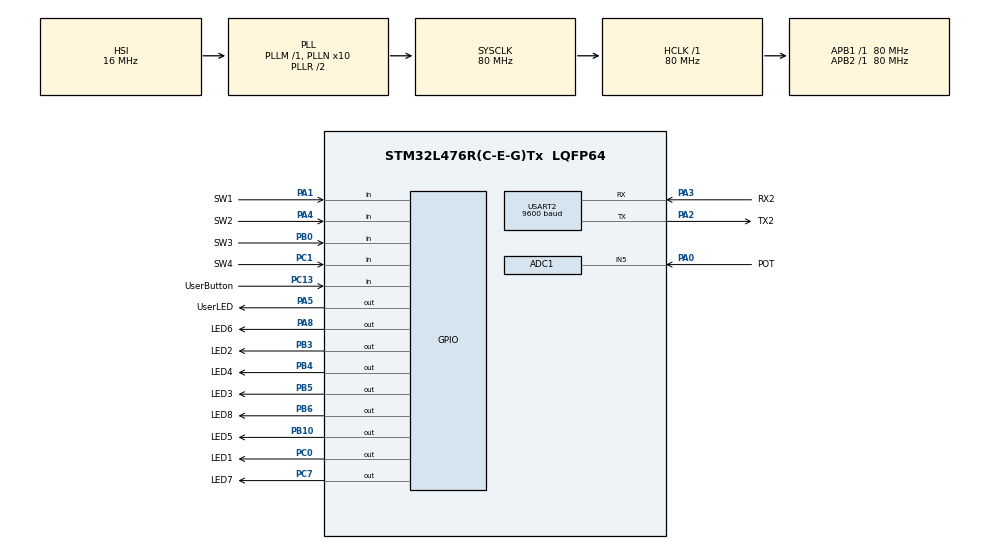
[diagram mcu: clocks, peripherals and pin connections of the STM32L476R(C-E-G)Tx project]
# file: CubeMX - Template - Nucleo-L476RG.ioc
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ADC1.Channel-0\#ChannelRegularConversion=ADC_CHANNEL_5
ADC1.NbrOfConversionFlag=1
ADC1.OffsetNumber-0\#ChannelRegularConversion=ADC_OFFSET_NONE
ADC1.Overrun=ADC_OVR_DATA_OVERWRITTEN
ADC1.Rank-0\#ChannelRegularConversion=1
ADC1.Resolution=ADC_RESOLUTION_12B
ADC1.SamplingTime-0\#ChannelRegularConversion=ADC_SAMPLETIME_2CYCLES_5
ADC1.master=1
Mcu.Family=STM32L4
Mcu.Name=STM32L476R(C-E-G)Tx
Mcu.Package=LQFP64
NVIC.PriorityGroup=NVIC_PRIORITYGROUP_4
NVIC.TIM6_DAC_IRQn=true\:0\:0\:false\:false\:true\:true\:true\:true
NVIC.USART2_IRQn=true\:0\:0\:false\:false\:true\:true\:true\:true
PA0.GPIO_Label=POT
PA0.Signal=ADCx_IN5
PA1.GPIO_Label=SW1
PA1.Signal=GPIO_Input
PA13\ (JTMS-SWDIO).GPIO_Label=TMS
PA13\ (JTMS-SWDIO).Mode=Serial_Wire
PA13\ (JTMS-SWDIO).Signal=SYS_JTMS-SWDIO
PA14\ (JTCK-SWCLK).GPIO_Label=TCK
PA14\ (JTCK-SWCLK).Mode=Serial_Wire
PA14\ (JTCK-SWCLK).Signal=SYS_JTCK-SWCLK
PA2.GPIO_Label=TX2
PA2.GPIO_Mode=GPIO_MODE_AF_PP
PA2.GPIO_PuPd=GPIO_NOPULL
PA2.GPIO_Speed=GPIO_SPEED_FREQ_VERY_HIGH
PA2.Mode=Asynchronous
PA2.Signal=USART2_TX
PA3.GPIO_Label=RX2
PA3.GPIO_Mode=GPIO_MODE_AF_PP
PA3.GPIO_PuPd=GPIO_NOPULL
PA3.GPIO_Speed=GPIO_SPEED_FREQ_VERY_HIGH
PA3.Mode=Asynchronous
PA3.Signal=USART2_RX
PA4.GPIO_Label=SW2
PA4.Signal=GPIO_Input
PA5.GPIO_Label=UserLED
PA5.GPIO_ModeDefaultOutputPP=GPIO_MODE_OUTPUT_PP
PA5.GPIO_PuPd=GPIO_NOPULL
PA5.GPIO_Speed=GPIO_SPEED_FREQ_LOW
PA5.Signal=GPIO_Output
PA8.GPIO_Label=LED6
PA8.Signal=GPIO_Output
PB0.GPIO_Label=SW3
PB0.Signal=GPIO_Input
PB10.GPIO_Label=LED5
PB10.Signal=GPIO_Output
PB3\ (JTDO-TRACESWO).GPIO_Label=LED2
PB3\ (JTDO-TRACESWO).Signal=GPIO_Output
PB4\ (NJTRST).GPIO_Label=LED4
PB4\ (NJTRST).Signal=GPIO_Output
PB5.GPIO_Label=LED3
PB5.Signal=GPIO_Output
PB6.GPIO_Label=LED8
PB6.Signal=GPIO_Output
PC0.GPIO_Label=LED1
PC0.Signal=GPIO_Output
PC1.GPIO_Label=SW4
PC1.Signal=GPIO_Input
PC13.GPIO_Label=UserButton
PC13.Signal=GPIO_Input
PC7.GPIO_Label=LED7
PC7.Signal=GPIO_Output
ProjectManager.HeapSize=0x200
ProjectManager.StackSize=0x400
ProjectManager.TargetToolchain=MDK-ARM V5.32
RCC.ADCFreq_Value=64000000
RCC.AHBFreq_Value=80000000
RCC.APB1Freq_Value=80000000
RCC.APB1TimFreq_Value=80000000
RCC.APB2Freq_Value=80000000
RCC.APB2TimFreq_Value=80000000
RCC.CortexFreq_Value=80000000
RCC.HCLKFreq_Value=80000000
RCC.HSE_VALUE=8000000
RCC.HSI_VALUE=16000000
RCC.LSE_VALUE=32768
RCC.MSI_VALUE=4000000
RCC.PLLN=10
RCC.PLLSourceVirtual=RCC_PLLSOURCE_HSI
RCC.PREFETCH_ENABLE=1
RCC.SYSCLKFreq_VALUE=80000000
RCC.SYSCLKSource=RCC_SYSCLKSOURCE_PLLCLK
RCC.USBFreq_Value=64000000
RCC.VCOOutputFreq_Value=160000000
SH.ADCx_IN5.0=ADC1_IN5,IN5-Single-Ended
USART2.BaudRate=9600
USART2.OverrunDisableParam=ADVFEATURE_OVERRUN_DISABLE
USART2.VirtualMode-Asynchronous=VM_ASYNC
VP_TIM6_VS_ClockSourceINT.Mode=Enable_Timer
board=NUCLEO-L476RG

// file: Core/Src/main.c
/* USER CODE BEGIN Header */
/**
  ******************************************************************************
  * @file           : main.c
  * @brief          : Main program body
  ******************************************************************************
  * @attention
  *
  * Copyright (c) 2023 STMicroelectronics.
  * All rights reserved.
  *
  * This software is licensed under terms that can be found in the LICENSE file
  * in the root directory of this software component.
  * If no LICENSE file comes with this software, it is provided AS-IS.
  *
  ******************************************************************************
  */
	// Versie: 20252026
/* USER CODE END Header */
#include "main.h"

/* USER CODE BEGIN Includes */
#include "leds.h"
#include "buttons.h"
#include "usart2.h"
#include "ad.h"
#include "stdio.h"
#include "string.h"
/* USER CODE END Includes */

ADC_HandleTypeDef hadc1;

TIM_HandleTypeDef htim6;

UART_HandleTypeDef huart2;

/* USER CODE BEGIN PV */
static uint8_t count = 0;
static char text[101];
/* USER CODE END PV */

void SystemClock_Config(void);
static void MX_GPIO_Init(void);
static void MX_ADC1_Init(void);
static void MX_USART2_UART_Init(void);
static void MX_TIM6_Init(void);

int main(void)
{

  /* MCU Configuration--------------------------------------------------------*/

  /* Reset of all peripherals, Initializes the Flash interface and the Systick. */
  HAL_Init();

  /* Configure the system clock */
  SystemClock_Config();

  /* Initialize all configured peripherals */
  MX_GPIO_Init();
  MX_ADC1_Init();
  MX_USART2_UART_Init();
  MX_TIM6_Init();
  /* USER CODE BEGIN 2 */
	// Laten weten dat we opgestart zijn, via de USART2 (USB).
	strcpy(text, "Reboot\r\n");
	printf("%s", text);
  /* USER CODE END 2 */

  /* Infinite loop */
  /* USER CODE BEGIN WHILE */
  while (1)
  {
		HAL_TIM_Base_Start_IT(&htim6);
    /* USER CODE END WHILE */

  }
}

void SystemClock_Config(void)
{
  RCC_OscInitTypeDef RCC_OscInitStruct = {0};
  RCC_ClkInitTypeDef RCC_ClkInitStruct = {0};

  /** Configure the main internal regulator output voltage
  */
  if (HAL_PWREx_ControlVoltageScaling(PWR_REGULATOR_VOLTAGE_SCALE1) != HAL_OK)
  {
    Error_Handler();
  }

  /** Initializes the RCC Oscillators according to the specified parameters
  * in the RCC_OscInitTypeDef structure.
  */
  RCC_OscInitStruct.OscillatorType = RCC_OSCILLATORTYPE_HSI;
  RCC_OscInitStruct.HSIState = RCC_HSI_ON;
  RCC_OscInitStruct.HSICalibrationValue = RCC_HSICALIBRATION_DEFAULT;
  RCC_OscInitStruct.PLL.PLLState = RCC_PLL_ON;
  RCC_OscInitStruct.PLL.PLLSource = RCC_PLLSOURCE_HSI;
  RCC_OscInitStruct.PLL.PLLM = 1;
  RCC_OscInitStruct.PLL.PLLN = 10;
  RCC_OscInitStruct.PLL.PLLP = RCC_PLLP_DIV7;
  RCC_OscInitStruct.PLL.PLLQ = RCC_PLLQ_DIV2;
  RCC_OscInitStruct.PLL.PLLR = RCC_PLLR_DIV2;
  if (HAL_RCC_OscConfig(&RCC_OscInitStruct) != HAL_OK)
  {
    Error_Handler();
  }

  /** Initializes the CPU, AHB and APB buses clocks
  */
  RCC_ClkInitStruct.ClockType = RCC_CLOCKTYPE_HCLK|RCC_CLOCKTYPE_SYSCLK
                              |RCC_CLOCKTYPE_PCLK1|RCC_CLOCKTYPE_PCLK2;
  RCC_ClkInitStruct.SYSCLKSource = RCC_SYSCLKSOURCE_PLLCLK;
  RCC_ClkInitStruct.AHBCLKDivider = RCC_SYSCLK_DIV1;
  RCC_ClkInitStruct.APB1CLKDivider = RCC_HCLK_DIV1;
  RCC_ClkInitStruct.APB2CLKDivider = RCC_HCLK_DIV1;

  if (HAL_RCC_ClockConfig(&RCC_ClkInitStruct, FLASH_LATENCY_4) != HAL_OK)
  {
    Error_Handler();
  }
}

static void MX_ADC1_Init(void)
{

  ADC_MultiModeTypeDef multimode = {0};
  ADC_ChannelConfTypeDef sConfig = {0};

  /** Common config
  */
  hadc1.Instance = ADC1;
  hadc1.Init.ClockPrescaler = ADC_CLOCK_ASYNC_DIV1;
  hadc1.Init.Resolution = ADC_RESOLUTION_12B;
  hadc1.Init.DataAlign = ADC_DATAALIGN_RIGHT;
  hadc1.Init.ScanConvMode = ADC_SCAN_DISABLE;
  hadc1.Init.EOCSelection = ADC_EOC_SINGLE_CONV;
  hadc1.Init.LowPowerAutoWait = DISABLE;
  hadc1.Init.ContinuousConvMode = DISABLE;
  hadc1.Init.NbrOfConversion = 1;
  hadc1.Init.DiscontinuousConvMode = DISABLE;
  hadc1.Init.ExternalTrigConv = ADC_SOFTWARE_START;
  hadc1.Init.ExternalTrigConvEdge = ADC_EXTERNALTRIGCONVEDGE_NONE;
  hadc1.Init.DMAContinuousRequests = DISABLE;
  hadc1.Init.Overrun = ADC_OVR_DATA_OVERWRITTEN;
  hadc1.Init.OversamplingMode = DISABLE;
  if (HAL_ADC_Init(&hadc1) != HAL_OK)
  {
    Error_Handler();
  }

  /** Configure the ADC multi-mode
  */
  multimode.Mode = ADC_MODE_INDEPENDENT;
  if (HAL_ADCEx_MultiModeConfigChannel(&hadc1, &multimode) != HAL_OK)
  {
    Error_Handler();
  }

  /** Configure Regular Channel
  */
  sConfig.Channel = ADC_CHANNEL_5;
  sConfig.Rank = ADC_REGULAR_RANK_1;
  sConfig.SamplingTime = ADC_SAMPLETIME_2CYCLES_5;
  sConfig.SingleDiff = ADC_SINGLE_ENDED;
  sConfig.OffsetNumber = ADC_OFFSET_NONE;
  sConfig.Offset = 0;
  if (HAL_ADC_ConfigChannel(&hadc1, &sConfig) != HAL_OK)
  {
    Error_Handler();
  }

}

static void MX_TIM6_Init(void)
{

  TIM_MasterConfigTypeDef sMasterConfig = {0};

  htim6.Instance = TIM6;
  htim6.Init.Prescaler = 7999;
  htim6.Init.CounterMode = TIM_COUNTERMODE_UP;
  htim6.Init.Period = 1999;
  htim6.Init.AutoReloadPreload = TIM_AUTORELOAD_PRELOAD_DISABLE;
  if (HAL_TIM_Base_Init(&htim6) != HAL_OK)
  {
    Error_Handler();
  }
  sMasterConfig.MasterOutputTrigger = TIM_TRGO_RESET;
  sMasterConfig.MasterSlaveMode = TIM_MASTERSLAVEMODE_DISABLE;
  if (HAL_TIMEx_MasterConfigSynchronization(&htim6, &sMasterConfig) != HAL_OK)
  {
    Error_Handler();
  }

}

static void MX_USART2_UART_Init(void)
{

  huart2.Instance = USART2;
  huart2.Init.BaudRate = 9600;
  huart2.Init.WordLength = UART_WORDLENGTH_8B;
  huart2.Init.StopBits = UART_STOPBITS_1;
  huart2.Init.Parity = UART_PARITY_NONE;
  huart2.Init.Mode = UART_MODE_TX_RX;
  huart2.Init.HwFlowCtl = UART_HWCONTROL_NONE;
  huart2.Init.OverSampling = UART_OVERSAMPLING_16;
  huart2.Init.OneBitSampling = UART_ONE_BIT_SAMPLE_DISABLE;
  huart2.AdvancedInit.AdvFeatureInit = UART_ADVFEATURE_RXOVERRUNDISABLE_INIT;
  huart2.AdvancedInit.OverrunDisable = UART_ADVFEATURE_OVERRUN_DISABLE;
  if (HAL_UART_Init(&huart2) != HAL_OK)
  {
    Error_Handler();
  }

}

static void MX_GPIO_Init(void)
{
  GPIO_InitTypeDef GPIO_InitStruct = {0};

  /* GPIO Ports Clock Enable */
  __HAL_RCC_GPIOC_CLK_ENABLE();
  __HAL_RCC_GPIOA_CLK_ENABLE();
  __HAL_RCC_GPIOB_CLK_ENABLE();

  /*Configure GPIO pin Output Level */
  HAL_GPIO_WritePin(GPIOC, LED1_Pin|LED7_Pin, GPIO_PIN_RESET);

  /*Configure GPIO pin Output Level */
  HAL_GPIO_WritePin(GPIOA, UserLED_Pin|LED6_Pin, GPIO_PIN_RESET);

  /*Configure GPIO pin Output Level */
  HAL_GPIO_WritePin(GPIOB, LED5_Pin|LED2_Pin|LED4_Pin|LED3_Pin
                          |LED8_Pin, GPIO_PIN_RESET);

  /*Configure GPIO pins : UserButton_Pin SW4_Pin */
  GPIO_InitStruct.Pin = UserButton_Pin|SW4_Pin;
  GPIO_InitStruct.Mode = GPIO_MODE_INPUT;
  GPIO_InitStruct.Pull = GPIO_NOPULL;
  HAL_GPIO_Init(GPIOC, &GPIO_InitStruct);

  /*Configure GPIO pins : LED1_Pin LED7_Pin */
  GPIO_InitStruct.Pin = LED1_Pin|LED7_Pin;
  GPIO_InitStruct.Mode = GPIO_MODE_OUTPUT_PP;
  GPIO_InitStruct.Pull = GPIO_NOPULL;
  GPIO_InitStruct.Speed = GPIO_SPEED_FREQ_LOW;
  HAL_GPIO_Init(GPIOC, &GPIO_InitStruct);

  /*Configure GPIO pins : SW1_Pin SW2_Pin */
  GPIO_InitStruct.Pin = SW1_Pin|SW2_Pin;
  GPIO_InitStruct.Mode = GPIO_MODE_INPUT;
  GPIO_InitStruct.Pull = GPIO_NOPULL;
  HAL_GPIO_Init(GPIOA, &GPIO_InitStruct);

  /*Configure GPIO pins : UserLED_Pin LED6_Pin */
  GPIO_InitStruct.Pin = UserLED_Pin|LED6_Pin;
  GPIO_InitStruct.Mode = GPIO_MODE_OUTPUT_PP;
  GPIO_InitStruct.Pull = GPIO_NOPULL;
  GPIO_InitStruct.Speed = GPIO_SPEED_FREQ_LOW;
  HAL_GPIO_Init(GPIOA, &GPIO_InitStruct);

  /*Configure GPIO pin : SW3_Pin */
  GPIO_InitStruct.Pin = SW3_Pin;
  GPIO_InitStruct.Mode = GPIO_MODE_INPUT;
  GPIO_InitStruct.Pull = GPIO_NOPULL;
  HAL_GPIO_Init(SW3_GPIO_Port, &GPIO_InitStruct);

  /*Configure GPIO pins : LED5_Pin LED2_Pin LED4_Pin LED3_Pin
                           LED8_Pin */
  GPIO_InitStruct.Pin = LED5_Pin|LED2_Pin|LED4_Pin|LED3_Pin
                          |LED8_Pin;
  GPIO_InitStruct.Mode = GPIO_MODE_OUTPUT_PP;
  GPIO_InitStruct.Pull = GPIO_NOPULL;
  GPIO_InitStruct.Speed = GPIO_SPEED_FREQ_LOW;
  HAL_GPIO_Init(GPIOB, &GPIO_InitStruct);

}

/* USER CODE BEGIN 4 */
void HAL_TIM_PeriodElapsedCallback(TIM_HandleTypeDef *htim)
{
	if(htim->Instance == TIM6)
	{
		ToggleLed(1);
	}
}
/* USER CODE END 4 */

void Error_Handler(void)
{
  __disable_irq();
  while (1)
  {
  }
}
#ifdef USE_FULL_ASSERT
/**
  * @brief  Reports the name of the source file and the source line number
  *         where the assert_param error has occurred.
  * @param  file: pointer to the source file name
  * @param  line: assert_param error line source number
  * @retval None
  */
void assert_failed(uint8_t *file, uint32_t line)
{
  /* USER CODE BEGIN 6 */
  /* User can add his own implementation to report the file name and line number,
     ex: printf("Wrong parameters value: file %s on line %d\r\n", file, line) */
// Versie: 20252026
  /* USER CODE END 6 */
}
#endif /* USE_FULL_ASSERT */
